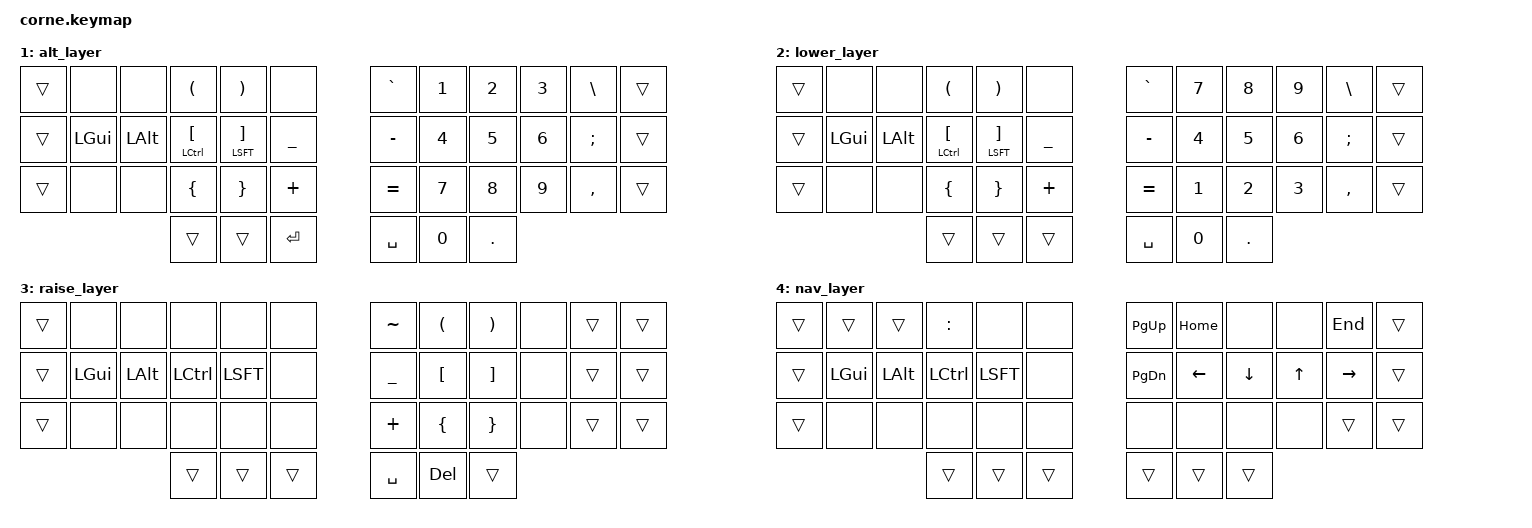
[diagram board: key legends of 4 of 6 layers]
/*
 * Copyright (c) 2021 The ZMK Contributors
 *
 * SPDX-License-Identifier: MIT
 */

#include <behaviors.dtsi>
#include <dt-bindings/zmk/keys.h>
#include <dt-bindings/zmk/bt.h>

#define DEFAULT 0
#define ALT 1
#define LOWER 2
#define RAISE 3
#define NAV 4
#define ADJUST 5

&caps_word {
    continue-list = <UNDERSCORE MINUS>;
};

/ {
    behaviors {
        hm: homerow_mods {
            compatible = "zmk,behavior-hold-tap";
            label = "HOMEROW_MODS";
            #binding-cells = <2>;
            tapping-term-ms = <125>;
            quick_tap_ms = <0>;
            flavor = "tap-preferred";
            bindings = <&kp>, <&kp>;
        };
        td: behavior_tap_dance_layer {
            compatible = "zmk,behavior-hold-tap";
            label = "TAP_DANCE";
            #binding-cells = <2>;
            tapping-term-ms = <200>;
            // quick_tap_ms = <0>;
            flavor = "hold-preferred";
            bindings = <&mo>, <&tog>;
        };
    };

    /* KEY POSITIONS
    -- from https://github.com/caksoylar/zmk-config/blob/main/config/combos.dtsi

    ╭────────────────────────╮ ╭────────────────────────╮
    │  0   1   2   3   4   5 │ │  6   7   8   9  10  11 │
    │ 12  13  14  15  16  17 │ │ 18  19  20  21  22  23 │
    │ 24  25  26  27  28  29 │ │ 30  31  32  33  34  35 │
    ╰───────────╮ 36  37  38 │ │ 39  40  41 ╭───────────╯
                ╰────────────╯ ╰────────────╯
    */
    combos {
        compatible = "zmk,combos";
        combo_semicolon {
            timeout-ms = <40>;
            key-positions = <7 8>;
            bindings = <&kp SEMI>;
        };
        combo_tab {
           timeout-ms = <40>;
           key-positions = <31 32>;
           bindings = <&kp TAB>;
        };
        combo_capslock {
            timeout-ms = <50>;
            key-positions = <6 18>;
            bindings = <&caps_word>;
       };
    };

    keymap {
        compatible = "zmk,keymap";

        default_layer {
// -----------------------------------------------------------------------------------------
// |   Q   |   W   |   F   |   P   |   B   | ----- |   J   |   L   |   U   |   Y   |  ' "  |
// |   A   |   R   |   S   |   T   |   G   | ----- |   M   |   N   |   E   |   I   |   O   |
// |   R   |   X   |   C   |   D   |   V   | ----- |   K   |   H   |  , <  |  . >  |  / ?  |
//                 |ADJ_ALT|LOW_TAB|RAI_ENT| ----- |NAV_SPC| HY_ESC|
            bindings = <
&trans &kp Q       &kp W       &kp F       &kp P       &kp B       &kp J   &kp L       &kp U       &kp Y       &kp APOS     &trans
&trans &hm LGUI A  &hm LALT R  &hm LCTL S  &hm LSFT T  &kp G       &kp M   &hm RSFT N  &hm RCTL E  &hm LALT I  &hm RGUI O   &trans
&trans &kp Z       &kp X       &kp C       &kp D       &kp V       &kp K   &kp H       &kp COMMA   &kp DOT     &kp FSLH     &trans
                 &td ADJUST ALT  &lt RAISE BSPC  &lt LOWER ENTER        &lt NAV SPACE   &mt LS(LC(LA(LGUI))) ESC    &kp DEL
            >;
        };

        alt_layer {
// -----------------------------------------------------------------------------------------
// |       |       |       |       |       | ----- |       |       |       |       |       |
// |       |       |       |       |       | ----- |       |       |       |       |       |
// |       |       |       |       |       | ----- |       |       |       |       |       |
//                         |       |       | ----- |       |       |
            bindings = <
&trans &none       &none       &kp LPAR      &kp RPAR      &none           &kp GRAVE   &kp N1  &kp N2  &kp N3  &kp BSLH    &trans
&trans &kp LGUI    &kp LALT    &hm LCTL LBKT &hm LSFT RBKT &kp UNDER       &kp MINUS   &kp N4  &kp N5  &kp N6  &kp SEMI    &trans
&trans &none       &none       &kp LBRC      &kp RBRC      &kp PLUS        &kp EQUAL   &kp N7  &kp N8  &kp N9  &kp COMMA   &trans
                        &trans        &trans        &kp ENTER          &kp SPACE   &kp N0 &kp DOT
            >;
        };

        lower_layer {
// -----------------------------------------------------------------------------------------
// |       |       |       |       |       | ----- |  ` ~  |  7 &  |  8 *  |  9 (  |  \ |  |
// | LGUI  | LALT  | LCTL  | LSFT  |  _    | ----- |  - _  |  4 _  |  5 %  |  6 ^  |  ; :  |
// |       |       |       |       |  , <  | ----- |  = +  |  1 !  |  2 @  |  3 #  |  . >  |
//                         |       |       | ----- |       |  0 )  |
// NOTE: Consider "&tog LOWER" instead of "&kp GRAVE"
            bindings = <
&trans &none       &none       &kp LPAR      &kp RPAR      &none           &kp GRAVE   &kp N7  &kp N8  &kp N9  &kp BSLH   &trans
&trans &kp LGUI    &kp LALT    &hm LCTL LBKT &hm LSFT RBKT &kp UNDER       &kp MINUS   &kp N4  &kp N5  &kp N6  &kp SEMI   &trans
&trans &none       &none       &kp LBRC      &kp RBRC      &kp PLUS        &kp EQUAL   &kp N1  &kp N2  &kp N3  &kp COMMA  &trans
                        &trans        &trans        &trans          &kp SPACE   &kp N0 &kp DOT
            >;
        };

        raise_layer {
// -----------------------------------------------------------------------------------------
// |       |       |       |       |  CAPS | ----- |   ~   |   (   |   )   |       |       |
// | LGUI  | LALT  | LCTL  | LSFT  |       | ----- |   _   |   [   |   ]   |       |       |
// |       |       |       |       |       | ----- |   +   |   {   |   }   |       |       |
//                         |  TAB  |       | ----- | BSPC  |  DEL  |
            bindings = <
&trans &none       &none       &none       &none       &none       &kp TILDE   &kp LPAR  &kp RPAR  &none  &trans   &trans
&trans &kp LGUI    &kp LALT    &kp LCTL    &kp LSFT    &none       &kp UNDER   &kp LBKT  &kp RBKT  &none  &trans   &trans
&trans &none       &none       &none       &none       &none       &kp PLUS    &kp LBRC  &kp RBRC  &none  &trans   &trans
                        &trans      &trans      &trans      &kp SPACE   &kp DEL   &trans
            >;
        };

        nav_layer {
// -----------------------------------------------------------------------------------------
// |       |       |   :   |       |       | ----- | PG_UP | HOME  |       |       |  END  |
// | LGUI  | LALT  | LCTL  | LSFT  |       | ----- | PG_DN | LEFT  | DOWN  |  UP   | RIGHT |
// |       |       |       |       |       | ----- |       |       |       |       |       |
//                         |  TAB  |       | ----- |       |       |
            bindings = <
&trans &trans      &trans      &kp COLON   &none       &none       &kp PG_UP  &kp HOME  &none    &none  &kp END     &trans
&trans &kp LGUI    &kp LALT    &kp LCTL    &kp LSFT    &none       &kp PG_DN  &kp LEFT  &kp DOWN &kp UP &kp RIGHT   &trans
&trans &none       &none       &none       &none       &none       &none      &none     &none    &none  &trans      &trans
                        &trans      &trans      &trans      &trans     &trans    &trans
            >;
        };

        adjust_layer {
// -----------------------------------------------------------------------------------------
// | BOOTL |       |       |  BT 1 |  BT O | ----- |DEFAULT|QWERTY |       |  BRIU |  VOLU |
// | RESET |       |       |  BT 2 |BT NXT | ----- |       |       |       |  BRID |  VOLD |
// | BT CLR|       |       |  BT 3 |BT PRV | ----- |  PREV |  NEXT |       |       |  MUTE |
//                         |       |       | ----- |  PLAY |  STOP |
            bindings = <
&trans &bootloader &none  &none  &bt BT_SEL 1  &bt BT_SEL 0     &to DEFAULT &none      &none       &kp C_BRI_UP &kp C_VOL_UP &trans
&trans &reset      &none  &none  &bt BT_SEL 2  &bt BT_NXT       &none       &none      &none       &kp C_BRI_DN &kp C_VOL_DN &trans
&trans &bt BT_CLR  &none  &none  &bt BT_SEL 3  &bt BT_PRV       &kp C_PP    &kp C_STOP &kp C_PREV  &kp C_NEXT   &kp C_MUTE   &trans
                        &trans        &trans           &none       &none
            >;
        };
    };
};
